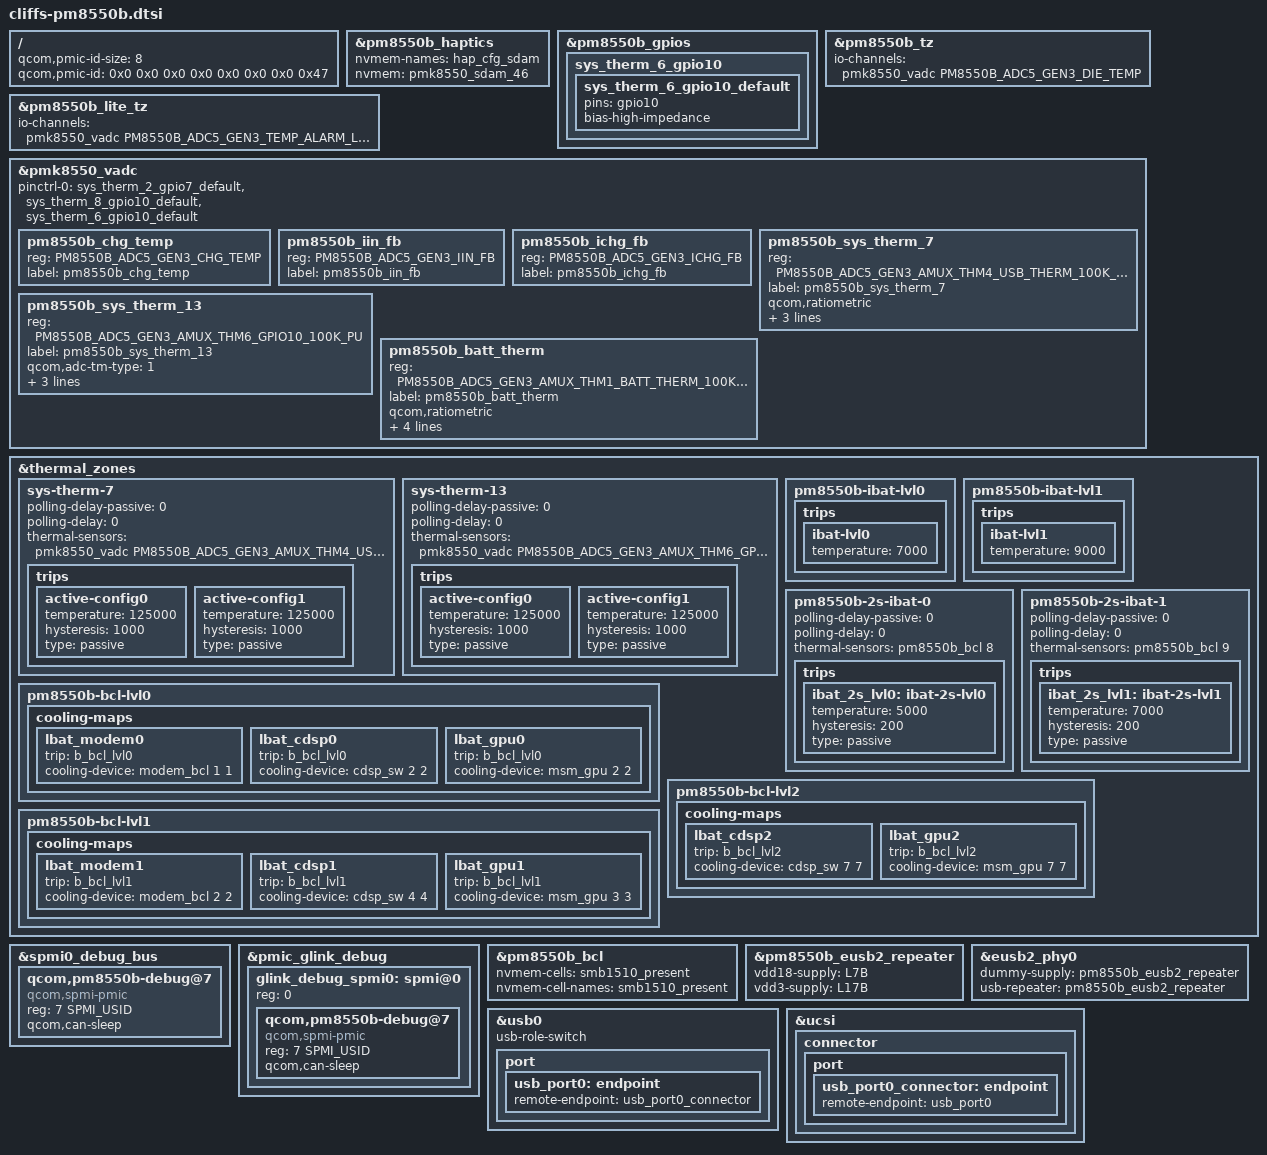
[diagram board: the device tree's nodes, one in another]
#include "pm8550b.dtsi"
#include <dt-bindings/iio/qcom,spmi-vadc.h>
#include <dt-bindings/iio/qcom,spmi-adc5-gen3-pm8550b.h>

/ {
	qcom,pmic-id-size = <8>;
	qcom,pmic-id = <0x0 0x0 0x0 0x0 0x0 0x0 0x0 0x47>;
};

&pm8550b_haptics {
	nvmem-names = "hap_cfg_sdam";
	nvmem = <&pmk8550_sdam_46>;
	status = "ok";
};

&pm8550b_gpios {
	sys_therm_6_gpio10 {
		sys_therm_6_gpio10_default: sys_therm_6_gpio10_default {
			pins = "gpio10";
			bias-high-impedance;
		};
	};
};

&pm8550b_tz {
	io-channels = <&pmk8550_vadc PM8550B_ADC5_GEN3_DIE_TEMP>;
	io-channel-names = "thermal";
};

&pm8550b_lite_tz {
	io-channels = <&pmk8550_vadc PM8550B_ADC5_GEN3_TEMP_ALARM_LITE>;
	io-channel-names = "thermal";
};

&pmk8550_vadc {
	pinctrl-0 = <&sys_therm_2_gpio7_default &sys_therm_8_gpio10_default &sys_therm_6_gpio10_default>;

	pm8550b_chg_temp {
		reg = <PM8550B_ADC5_GEN3_CHG_TEMP>;
		label = "pm8550b_chg_temp";
	};

	pm8550b_iin_fb {
		reg = <PM8550B_ADC5_GEN3_IIN_FB>;
		label = "pm8550b_iin_fb";
	};

	pm8550b_ichg_fb {
		reg = <PM8550B_ADC5_GEN3_ICHG_FB>;
		label = "pm8550b_ichg_fb";
	};

	pm8550b_sys_therm_7 {
		reg = <PM8550B_ADC5_GEN3_AMUX_THM4_USB_THERM_100K_PU>;
		label = "pm8550b_sys_therm_7";
		qcom,ratiometric;
		qcom,hw-settle-time = <200>;
		qcom,pre-scaling = <1 1>;
		qcom,adc-tm-type = <1>;

	};

	pm8550b_sys_therm_13 {
		reg = <PM8550B_ADC5_GEN3_AMUX_THM6_GPIO10_100K_PU>;
		label = "pm8550b_sys_therm_13";
		qcom,adc-tm-type = <1>;
		qcom,ratiometric;
		qcom,hw-settle-time = <200>;
		qcom,pre-scaling = <1 1>;
	};

	pm8550b_batt_therm {
		reg = <PM8550B_ADC5_GEN3_AMUX_THM1_BATT_THERM_100K_PU>;
		label = "pm8550b_batt_therm";
		qcom,ratiometric;
		qcom,hw-settle-time = <200>;
		qcom,pre-scaling = <1 1>;
		qcom,scale-fn-type = <ADC_SCALE_HW_CALIB_PM5_GEN3_BATT_THERM_100K>;
	};
};

&thermal_zones {
	sys-therm-7 {
		polling-delay-passive = <0>;
		polling-delay = <0>;
		thermal-sensors = <&pmk8550_vadc PM8550B_ADC5_GEN3_AMUX_THM4_USB_THERM_100K_PU>;
		trips {
			active-config0 {
				temperature = <125000>;
				hysteresis = <1000>;
				type = "passive";
			};

			active-config1 {
				temperature = <125000>;
				hysteresis = <1000>;
				type = "passive";
			};
		};
	};

	sys-therm-13 {
		polling-delay-passive = <0>;
		polling-delay = <0>;
		thermal-sensors = <&pmk8550_vadc PM8550B_ADC5_GEN3_AMUX_THM6_GPIO10_100K_PU>;
		trips {
			active-config0 {
				temperature = <125000>;
				hysteresis = <1000>;
				type = "passive";
			};

			active-config1 {
				temperature = <125000>;
				hysteresis = <1000>;
				type = "passive";
			};
		};
	};
};

&spmi0_debug_bus {
	qcom,pm8550b-debug@7 {
		compatible = "qcom,spmi-pmic";
		reg = <7 SPMI_USID>;
		#address-cells = <2>;
		#size-cells = <0>;
		qcom,can-sleep;
	};
};

&pmic_glink_debug {
	/* Primary SPMI bus */
	glink_debug_spmi0:
	spmi@0 {
		reg = <0>;
		#address-cells = <2>;
		#size-cells = <0>;

		qcom,pm8550b-debug@7 {
			compatible = "qcom,spmi-pmic";
			reg = <7 SPMI_USID>;
			qcom,can-sleep;
			};
	};
};

&pm8550b_bcl {
	nvmem-cells = <&smb1510_present>;
	nvmem-cell-names = "smb1510_present";
};

&thermal_zones {
	pm8550b-ibat-lvl0 {
		trips {
			ibat-lvl0 {
				temperature = <7000>;
			};
		};
	};

	pm8550b-ibat-lvl1 {
		trips {
			ibat-lvl1 {
				temperature = <9000>;
			};
		};
	};

	pm8550b-2s-ibat-0 {
		polling-delay-passive = <0>;
		polling-delay = <0>;
		thermal-sensors = <&pm8550b_bcl 8>;

		trips {
			ibat_2s_lvl0: ibat-2s-lvl0 {
				temperature = <5000>;
				hysteresis = <200>;
				type = "passive";
			};
		};
	};

	pm8550b-2s-ibat-1 {
		polling-delay-passive = <0>;
		polling-delay = <0>;
		thermal-sensors = <&pm8550b_bcl 9>;

		trips {
			ibat_2s_lvl1: ibat-2s-lvl1 {
				temperature = <7000>;
				hysteresis = <200>;
				type = "passive";
			};
		};
	};

	pm8550b-bcl-lvl0 {
		cooling-maps {
			lbat_modem0 {
				trip = <&b_bcl_lvl0>;
				cooling-device = <&modem_bcl 1 1>;
			};

			lbat_cdsp0 {
				trip = <&b_bcl_lvl0>;
				cooling-device = <&cdsp_sw 2 2>;
			};

			lbat_gpu0 {
				trip = <&b_bcl_lvl0>;
				cooling-device = <&msm_gpu 2 2>;
			};
		};
	};

	pm8550b-bcl-lvl1 {
		cooling-maps {
			lbat_modem1 {
				trip = <&b_bcl_lvl1>;
				cooling-device = <&modem_bcl 2 2>;
			};

			lbat_cdsp1 {
				trip = <&b_bcl_lvl1>;
				cooling-device = <&cdsp_sw 4 4>;
			};

			lbat_gpu1 {
				trip = <&b_bcl_lvl1>;
				cooling-device = <&msm_gpu 3 3>;
			};
		};
	};

	pm8550b-bcl-lvl2 {
		cooling-maps {
			lbat_cdsp2 {
				trip = <&b_bcl_lvl2>;
				cooling-device = <&cdsp_sw 7 7>;
			};

			lbat_gpu2 {
				trip = <&b_bcl_lvl2>;
				cooling-device = <&msm_gpu 7 7>;
			};
		};
	};
};

&pm8550b_eusb2_repeater {
	status = "ok";
	vdd18-supply = <&L7B>;
	vdd3-supply = <&L17B>;
};

&eusb2_phy0 {
	dummy-supply = <&pm8550b_eusb2_repeater>;
	usb-repeater = <&pm8550b_eusb2_repeater>;
};

&usb0 {
	usb-role-switch;
	port {
		usb_port0: endpoint {
			remote-endpoint = <&usb_port0_connector>;
		};
	};
};

&ucsi {
	connector {
		port {
			usb_port0_connector: endpoint {
				remote-endpoint = <&usb_port0>;
			};
		};
	};
};
